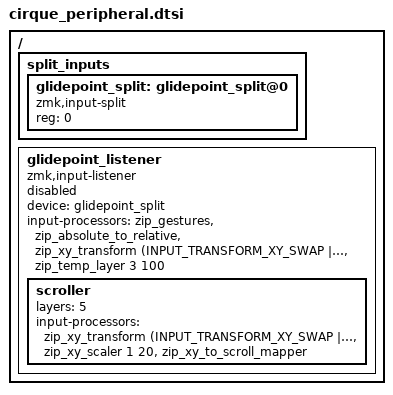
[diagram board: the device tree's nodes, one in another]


/ {
    split_inputs {
        #address-cells = <1>;
        #size-cells = <0>;

        glidepoint_split: glidepoint_split@0 {
            compatible = "zmk,input-split";
            reg = <0>;
        };
    };

    glidepoint_listener: glidepoint_listener {
        compatible = "zmk,input-listener";
        status = "disabled";
        device = <&glidepoint_split>;
    };
};

#include <dt-bindings/zmk/input_transform.h>
#include <input/processors.dtsi>
#include <dt-bindings/zmk/input_transform.h>
#include <behaviors/input_processor_gestures.dtsi>
#include <behaviors/input_processor_absolute_to_relative.dtsi>

/ {
    glidepoint_listener {
        compatible = "zmk,input-listener";
        device = <&glidepoint_split>;
        
        input-processors = <
            &zip_gestures
            &zip_absolute_to_relative
            &zip_xy_transform (INPUT_TRANSFORM_XY_SWAP | INPUT_TRANSFORM_Y_INVERT)
            &zip_temp_layer 3 100
        >;
        scroller {
            layers = <5>;
            input-processors = <
                &zip_xy_transform (INPUT_TRANSFORM_XY_SWAP | INPUT_TRANSFORM_X_INVERT)
                &zip_xy_scaler 1 20
                &zip_xy_to_scroll_mapper
            >;
        };
    };
};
